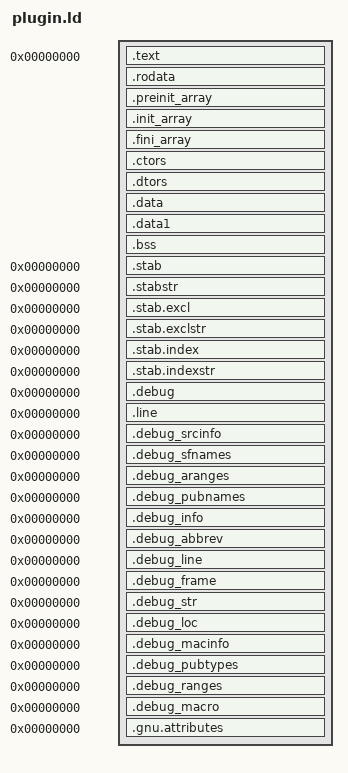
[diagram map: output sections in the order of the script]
/* ScummVM - Graphic Adventure Engine
 *
 * ScummVM is the legal property of its developers, whose names
 * are too numerous to list here. Please refer to the COPYRIGHT
 * file distributed with this source distribution.
 *
 * This program is free software: you can redistribute it and/or modify
 * it under the terms of the GNU General Public License as published by
 * the Free Software Foundation, either version 3 of the License, or
 * (at your option) any later version.
 *
 * This program is distributed in the hope that it will be useful,
 * but WITHOUT ANY WARRANTY; without even the implied warranty of
 * MERCHANTABILITY or FITNESS FOR A PARTICULAR PURPOSE.  See the
 * GNU General Public License for more details.
 *
 * You should have received a copy of the GNU General Public License
 * along with this program.  If not, see <http://www.gnu.org/licenses/>.
 *
 */

OUTPUT_FORMAT("elf32-m68k")
OUTPUT_ARCH(m68k)
ENTRY(_start)

PHDRS
{
	/* ScummVM's elf loader only allows a single segment. */
	plugin PT_LOAD FLAGS(7) /* Read | Write | Execute */;
}

SECTIONS
{
	. = 0;

	.text ALIGN(4) :
	{
		*(.text.unlikely .text.*_unlikely .text.unlikely.*)
		*(.text.exit .text.exit.*)
		*(.text.startup .text.startup.*)
		*(.text.hot .text.hot.*)
		*(.text .stub .text.* .gnu.linkonce.t.*)
		*(.gnu.warning)
	} : plugin

	.rodata ALIGN(4) :
	{
		*(.rodata)
		*(.rodata.*)
		*(.gnu.linkonce.r*)
		*(.rodata1)
		. = ALIGN(4);
	} : plugin

	.preinit_array ALIGN(4) :
	{
		PROVIDE (__preinit_array_start = .);
		KEEP (*(.preinit_array))
		PROVIDE (__preinit_array_end = .);
	} : plugin

	.init_array ALIGN(4) :
	{
		PROVIDE (__init_array_start = .);
		KEEP (*(SORT(.init_array.*)))
		KEEP (*(.init_array))
		PROVIDE (__init_array_end = .);
	} : plugin

	.fini_array ALIGN(4) :
	{
		PROVIDE (__fini_array_start = .);
		KEEP (*(.fini_array))
		KEEP (*(SORT(.fini_array.*)))
		PROVIDE (__fini_array_end = .);
	} : plugin

	.ctors ALIGN(4) :
	{
		___plugin_ctors = .;
		KEEP (*(SORT(.ctors.*)))
		KEEP (*(.ctors))
		___plugin_ctors_end = .;
	} : plugin

	.dtors ALIGN(4) :
	{
		___plugin_dtors = .;
		KEEP (*(SORT(.dtors.*)))
		KEEP (*(.dtors))
		___plugin_dtors_end = .;
	} : plugin

	.data ALIGN(4) :
	{
		*(.data)
		*(.data.*)
		*(.gnu.linkonce.d*)
		CONSTRUCTORS
		. = ALIGN(4);
	} : plugin
	.data1 :
	{
		*(.data1)
		. = ALIGN(4);
	} : plugin

	__bss_start__ = .;
	.bss ALIGN(4) :
	{
		*(.dynbss)
		*(.bss)
		*(SORT(.bss.*))
		*(.gnu.linkonce.b*)
		*(COMMON)
		. = ALIGN(4);
	} : plugin
	__bss_end__ = .;

	__end__ = ABSOLUTE(.) ;

	/* Discard sections that complicate post-processing */
	/DISCARD/ : { *(.group .comment .note) }

	/* Stabs debugging sections. */
	.stab          0 : { *(.stab) }
	.stabstr       0 : { *(.stabstr) }
	.stab.excl     0 : { *(.stab.excl) }
	.stab.exclstr  0 : { *(.stab.exclstr) }
	.stab.index    0 : { *(.stab.index) }
	.stab.indexstr 0 : { *(.stab.indexstr) }

	/* DWARF debug sections.
	   Symbols in the DWARF debugging sections are relative to the beginning
	   of the section so we begin them at 0. */

	/* DWARF 1 */
	.debug          0 : { *(.debug) }
	.line           0 : { *(.line) }

	/* GNU DWARF 1 extensions */
	.debug_srcinfo  0 : { *(.debug_srcinfo) }
	.debug_sfnames  0 : { *(.debug_sfnames) }

	/* DWARF 1.1 and DWARF 2 */
	.debug_aranges  0 : { *(.debug_aranges) }
	.debug_pubnames 0 : { *(.debug_pubnames) }

	/* DWARF 2 */
	.debug_info     0 : { *(.debug_info) }
	.debug_abbrev   0 : { *(.debug_abbrev) }
	.debug_line     0 : { *(.debug_line) }
	.debug_frame    0 : { *(.debug_frame) }
	.debug_str      0 : { *(.debug_str) }
	.debug_loc      0 : { *(.debug_loc) }
	.debug_macinfo  0 : { *(.debug_macinfo) }

	/* DWARF 3 */
	.debug_pubtypes 0 : { *(.debug_pubtypes) }
	.debug_ranges   0 : { *(.debug_ranges) }

	/* DWARF Extension. */
	.debug_macro    0 : { *(.debug_macro) }
	.gnu.attributes 0 : { KEEP (*(.gnu.attributes)) }

	/DISCARD/ : { *(.note.GNU-stack) *(.gnu_debuglink) *(.gnu.lto_*) }
}
